VERSION ""

NS_ :

BU_: EBCM ADAS PCM EPS VSA SCM BDY XXX EPB EON

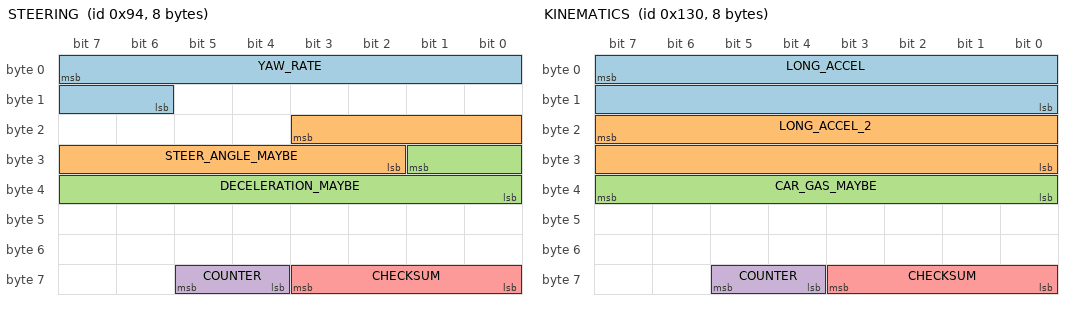
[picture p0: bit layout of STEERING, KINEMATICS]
BO_ 148 STEERING: 8 XXX
    SG_ YAW_RATE : 7|10@0+ (0.239494,-122.500631) [0.0|0.0] "deg/s" XXX
    SG_ STEER_ANGLE_MAYBE : 19|10@0+ (1,0) [0.0|0.0] "deg" XXX
    SG_ DECELERATION_MAYBE : 25|10@0+ (1,0) [0.0|0.0] "m/s2" XXX
    SG_ COUNTER : 61|2@0+ (1,0) [0|3] "" EON
    SG_ CHECKSUM : 59|4@0+ (1,0) [0|15] "" EON

BO_ 304 KINEMATICS: 8 XXX
    SG_ LONG_ACCEL : 7|16@0- (0.001168,0.0) [0.0|0.0] "m/s2" XXX
    SG_ LONG_ACCEL_2 : 23|16@0- (0.001168,0.0) [0.0|0.0] "m/s2" XXX
    SG_ CAR_GAS_MAYBE : 39|8@0+ (1,0) [0|255] "" EON
    SG_ COUNTER : 61|2@0+ (1,0) [0|3] "" EON
    SG_ CHECKSUM : 59|4@0+ (1,0) [0|15] "" EON

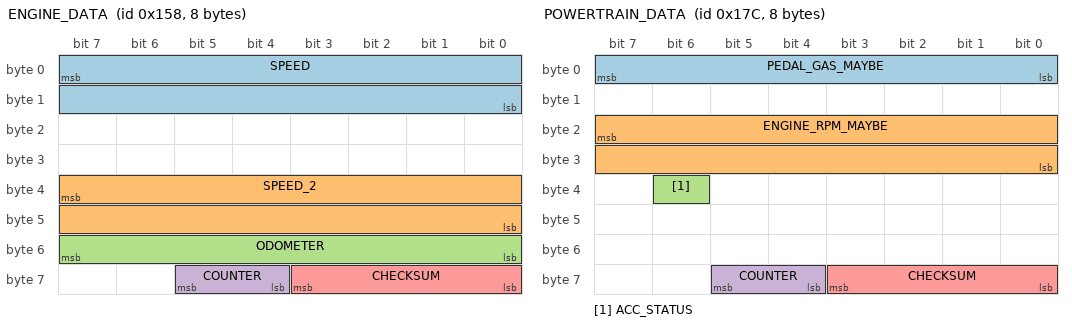
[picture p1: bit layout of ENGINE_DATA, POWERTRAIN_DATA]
BO_ 344 ENGINE_DATA: 8 PCM
    SG_ SPEED : 7|16@0+ (0.01,0) [0|250] "kph" EON
    SG_ SPEED_2 : 39|16@0+ (0.01,0) [0|250] "kph" EON
    SG_ ODOMETER : 55|8@0+ (10,0) [0|2550] "m" XXX
    SG_ COUNTER : 61|2@0+ (1,0) [0|3] "" EON
    SG_ CHECKSUM : 59|4@0+ (1,0) [0|15] "" EON

BO_ 380 POWERTRAIN_DATA: 8 PCM
    SG_ PEDAL_GAS_MAYBE : 7|8@0+ (1,0) [0|255] "" EON
    SG_ ENGINE_RPM_MAYBE : 23|16@0+ (1,0) [0|15000] "rpm" EON
    SG_ ACC_STATUS : 38|1@0+ (1,0) [0|1] "" EON
    SG_ COUNTER : 61|2@0+ (1,0) [0|3] "" EON
    SG_ CHECKSUM : 59|4@0+ (1,0) [0|3] "" EON

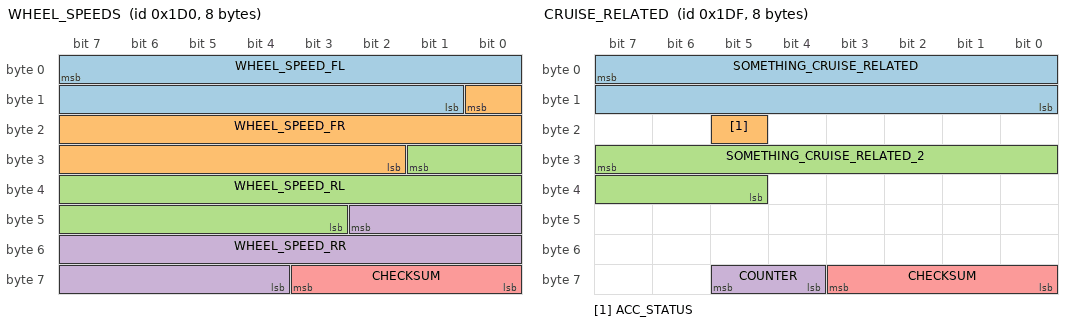
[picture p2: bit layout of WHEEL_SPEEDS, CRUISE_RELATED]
BO_ 464 WHEEL_SPEEDS: 8 VSA
    SG_ WHEEL_SPEED_FL : 7|15@0+ (0.01,0) [0|250] "kph" EON
    SG_ WHEEL_SPEED_FR : 8|15@0+ (0.01,0) [0|250] "kph" EON
    SG_ WHEEL_SPEED_RL : 25|15@0+ (0.01,0) [0|250] "kph" EON
    SG_ WHEEL_SPEED_RR : 42|15@0+ (0.01,0) [0|250] "kph" EON
    SG_ CHECKSUM : 59|4@0+ (1,0) [0|3] "" EON

BO_ 479 CRUISE_RELATED: 8 XXX
    SG_ SOMETHING_CRUISE_RELATED : 7|16@0- (1,0) [0.0|0.0] "" XXX
    SG_ ACC_STATUS : 21|1@0+ (1,0) [0.0|0.0] "" XXX
    SG_ SOMETHING_CRUISE_RELATED_2 : 31|11@0- (1,0) [0.0|0.0] "" XXX
    SG_ COUNTER : 61|2@0+ (1,0) [0|3] "" EON
    SG_ CHECKSUM : 59|4@0+ (1,0) [0|3] "" EON

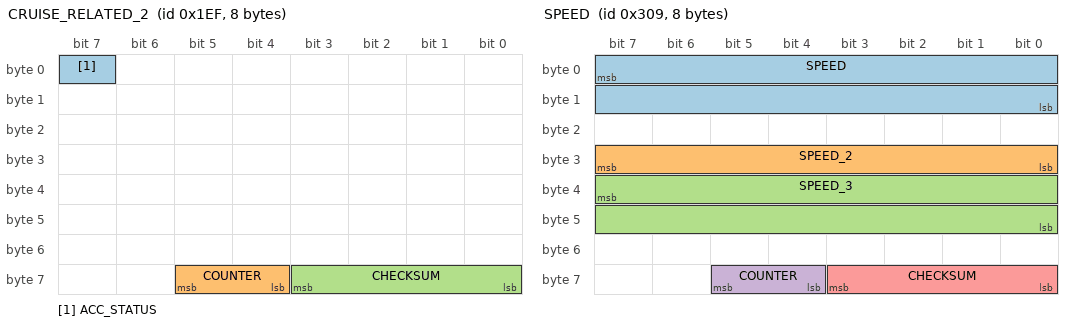
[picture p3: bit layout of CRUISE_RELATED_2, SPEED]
BO_ 495 CRUISE_RELATED_2: 8 XXX
    SG_ ACC_STATUS : 7|1@0+ (1,0) [0.0|0.0] "" XXX
    SG_ COUNTER : 61|2@0+ (1,0) [0|3] "" EON
    SG_ CHECKSUM : 59|4@0+ (1,0) [0|3] "" EON

BO_ 777 SPEED: 8 XXX
    SG_ SPEED : 7|16@0+ (0.01,0.0) [0.0|0.0] "m/s" XXX
    SG_ SPEED_2 : 31|8@0+ (1.764304,0.0) [0.0|0.0] "m/s" XXX
    SG_ SPEED_3 : 39|16@0+ (0.01,0.0) [0.0|0.0] "m/s" XXX
    SG_ COUNTER : 61|2@0+ (1,0) [0|3] "" EON
    SG_ CHECKSUM : 59|4@0+ (1,0) [0|15] "" EON

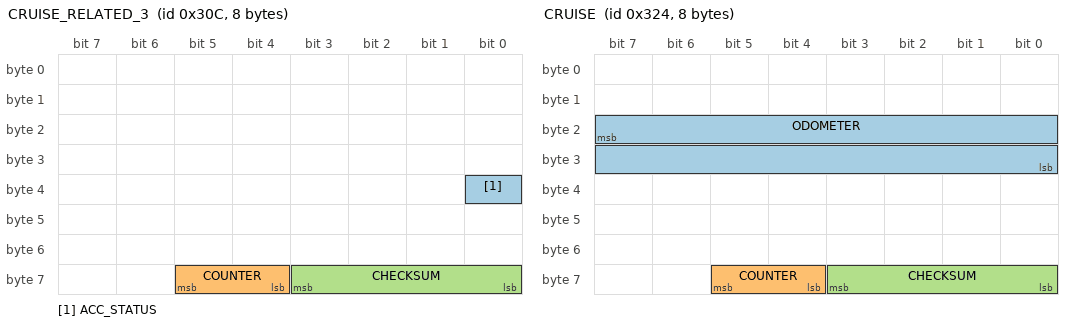
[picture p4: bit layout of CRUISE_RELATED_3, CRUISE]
BO_ 780 CRUISE_RELATED_3: 8 XXX
    SG_ ACC_STATUS : 32|1@0+ (1,0) [0.0|0.0] "" XXX
    SG_ COUNTER : 61|2@0+ (1,0) [0|3] "" EON
    SG_ CHECKSUM : 59|4@0+ (1,0) [0|3] "" EON

BO_ 804 CRUISE: 8 XXX
    SG_ ODOMETER : 23|16@0+ (0.002,0.0) [0.0|0.0] "km" XXX
    SG_ COUNTER : 61|2@0+ (1,0) [0|3] "" EON
    SG_ CHECKSUM : 59|4@0+ (1,0) [0|15] "" EON

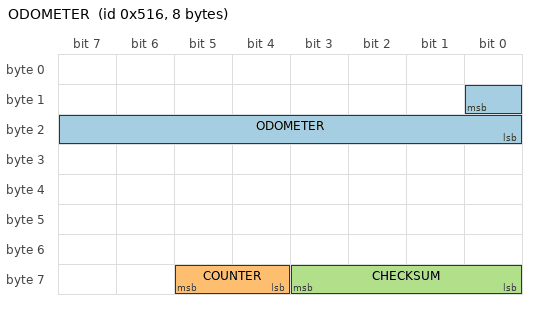
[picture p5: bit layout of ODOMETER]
BO_ 1302 ODOMETER: 8 XXX
    SG_ ODOMETER : 8|9@0+ (1.101895,0.0) [0.0|0.0] "m/s2" XXX
    SG_ COUNTER : 61|2@0+ (1,0) [0|3] "" EON
    SG_ CHECKSUM : 59|4@0+ (1,0) [0|15] "" EON
